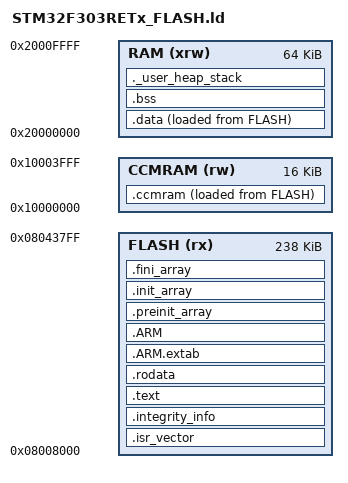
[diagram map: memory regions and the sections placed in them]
/*
*****************************************************************************
**

**  File        : LinkerScript.ld
**
**  Abstract    : Linker script for STM32F303RETx Device with
**                512KByte FLASH, 64KByte RAM
**
**                Set heap size, stack size and stack location according
**                to application requirements.
**
**                Set memory bank area and size if external memory is used.
**
**  Target      : STMicroelectronics STM32
**
**
**  Distribution: The file is distributed as is, without any warranty
**                of any kind.
**
**  (c)Copyright Ac6.
**  You may use this file as-is or modify it according to the needs of your
**  project. Distribution of this file (unmodified or modified) is not
**  permitted. Ac6 permit registered System Workbench for MCU users the
**  rights to distribute the assembled, compiled & linked contents of this
**  file as part of an application binary file, provided that it is built
**  using the System Workbench for MCU toolchain.
**
*****************************************************************************
*/

/* Entry Point */
ENTRY(Reset_Handler)

/* Total size of the flash memory is 512K, split into pages of 2K (0x800) */

/* Highest address of the user mode stack */
_estack = 0x20010000;    /* end of RAM */
__stack = _estack;
/* Generate a link error if heap and stack don't fit into RAM */
_Min_Heap_Size = 0x200;      /* required amount of heap  */
_Min_Stack_Size = 0x400; /* required amount of stack */

_flash_offset = 32K; /* first 32K is occupied by bootloader shim */
_flash_start = 0x8000000;
_app_flash_start  = _flash_start + _flash_offset;
_flash_size = 512K;
/* Length reduced by 4K to reserve last two pages for 
 * serial number and thermal offsets storage */
_serial_size = 4K; 
/* Remaining space is 512K - 32K - 4K =  476. This is divided in half to
 * leave room for a backup image, giving 238K for the image.*/
_app_flash_size = 238K;

/* Specify the memory areas */
MEMORY
{
FLASH (rx)      : ORIGIN = _app_flash_start, LENGTH = _app_flash_size 
RAM (xrw)      : ORIGIN = 0x20000000, LENGTH = 64K
CCMRAM (rw)      : ORIGIN = 0x10000000, LENGTH = 16K
}

/* Define output sections */
SECTIONS
{
  /* The startup code goes first into FLASH */
  .isr_vector :
  {
    . = ALIGN(4);
    KEEP(*(.isr_vector)) /* Startup code */
    . = ALIGN(4);
  } >FLASH

  /* Contains firmware authentication information */
  .integrity_info BLOCK(0x200) :
  {
    . = ALIGN(4);
    /* placeholder for CRC */
    ._integrity_crc = .;
    LONG(0);
    /* placeholder for firmware length */
    ._integrity_length = .;
    LONG(0);
    /* placeholder for firmware crc start address */
    ._integrity_start = .;
    LONG(0);
    /* placeholder for start of firmware name */
    ._integrity_name = .;
    LONG(0);
  } >FLASH

  /* The program code and other data goes into FLASH */
  .text BLOCK(0x200) :
  {
    . = ALIGN(4);
    *(.text)           /* .text sections (code) */
    *(.text*)          /* .text* sections (code) */
    *(.glue_7)         /* glue arm to thumb code */
    *(.glue_7t)        /* glue thumb to arm code */
    *(.eh_frame)
    *(.got)
    *(.got*)
    KEEP (*(.init))
    KEEP (*(.fini))

    . = ALIGN(4);
    _etext = .;        /* define a global symbols at end of code */
  } >FLASH

  /* Constant data goes into FLASH */
  .rodata :
  {
    . = ALIGN(4);
    *(.rodata)         /* .rodata sections (constants, strings, etc.) */
    *(.rodata*)        /* .rodata* sections (constants, strings, etc.) */
    . = ALIGN(4);
  } >FLASH

  .ARM.extab   : { *(.ARM.extab* .gnu.linkonce.armextab.*) } >FLASH
  .ARM : {
    __exidx_start = .;
    *(.ARM.exidx*)
    __exidx_end = .;
  } >FLASH

  .preinit_array     :
  {
    PROVIDE_HIDDEN (__preinit_array_start = .);
    KEEP (*(.preinit_array*))
    PROVIDE_HIDDEN (__preinit_array_end = .);
  } >FLASH
  .init_array :
  {
    PROVIDE_HIDDEN (__init_array_start = .);
    KEEP (*(SORT(.init_array.*)))
    KEEP (*(.init_array*))
    PROVIDE_HIDDEN (__init_array_end = .);
  } >FLASH
  .fini_array :
  {
    PROVIDE_HIDDEN (__fini_array_start = .);
    KEEP (*(SORT(.fini_array.*)))
    KEEP (*(.fini_array*))
    PROVIDE_HIDDEN (__fini_array_end = .);
  } >FLASH

  /* used by the startup to initialize data */
  _sidata = LOADADDR(.data);

  /* Initialized data sections goes into RAM, load LMA copy after code */
  .data : 
  {
    . = ALIGN(4);
    _sdata = .;        /* create a global symbol at data start */
    *(.data)           /* .data sections */
    *(.data*)          /* .data* sections */

    . = ALIGN(4);
    _edata = .;        /* define a global symbol at data end */
  } >RAM AT> FLASH

  _siccmram = LOADADDR(.ccmram);

  /* CCM-RAM section 
  * 
  * IMPORTANT NOTE! 
  * If initialized variables will be placed in this section,
  * the startup code needs to be modified to copy the init-values.  
  */
  .ccmram :
  {
    . = ALIGN(4);
    _sccmram = .;       /* create a global symbol at ccmram start */
    *(.ccmram)
    *(.ccmram*)
    
    . = ALIGN(4);
    _eccmram = .;       /* create a global symbol at ccmram end */
  } >CCMRAM AT> FLASH

  
  /* Uninitialized data section */
  . = ALIGN(4);
  .bss :
  {
    /* This is used by the startup in order to initialize the .bss secion */
    _sbss = .;         /* define a global symbol at bss start */
    __bss_start__ = _sbss;
    *(.bss)
    *(.bss*)
    *(COMMON)

    . = ALIGN(4);
    _ebss = .;         /* define a global symbol at bss end */
    __bss_end__ = _ebss;
  } >RAM



  /* User_heap_stack section, used to check that there is enough RAM left */
  ._user_heap_stack :
  {
    . = ALIGN(8);
    PROVIDE ( end = . );
    PROVIDE ( _end = . );
    . = . + _Min_Heap_Size;
    . = . + _Min_Stack_Size;
    . = ALIGN(8);
  } >RAM

  

  /* Remove information from the standard libraries */
  /DISCARD/ :
  {
    libc.a ( * )
    libm.a ( * )
    libgcc.a ( * )
  }

  .ARM.attributes 0 : { *(.ARM.attributes) }
}


